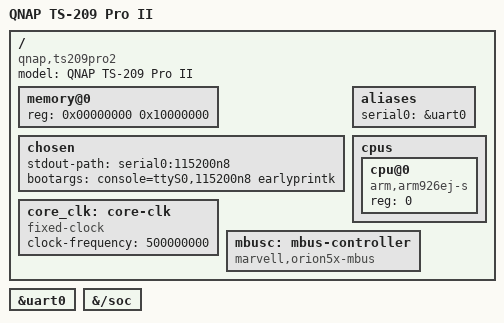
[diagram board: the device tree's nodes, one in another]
/dts-v1/;

#include "orion5x.dtsi"

/ {
    model = "QNAP TS-209 Pro II";
    compatible = "qnap,ts209pro2",
                 "marvell,rd-88f5182-nas-2-le",
                 "marvell,orion5x-88f5182";

    #address-cells = <1>;
    #size-cells = <1>;

    memory@0 {
        device_type = "memory";
        reg = <0x00000000 0x10000000>; /* 256MB */
    };

    chosen {
        stdout-path = "serial0:115200n8";
        bootargs = "console=ttyS0,115200n8 earlyprintk";
    };

    aliases {
        serial0 = &uart0;
    };

    cpus {
        #address-cells = <1>;
        #size-cells = <0>;

        cpu@0 {
            device_type = "cpu";
            compatible = "arm,arm926ej-s";
            reg = <0>;
        };
    };
};

/* Enable UART0 from the SoC definition */
&uart0 {
    status = "okay";
};

/* Ensure the SoC node is valid */
&{/soc} {
    #address-cells = <1>;
    #size-cells = <1>;
    ranges;
};

/ {
    core_clk: core-clk {
        compatible = "fixed-clock";
        #clock-cells = <1>;
        clock-frequency = <500000000>; /* placeholder */
    };

    mbusc: mbus-controller {
        compatible = "marvell,orion5x-mbus", "simple-bus";
        #address-cells = <1>;
        #size-cells = <1>;
        ranges;
    };
};

